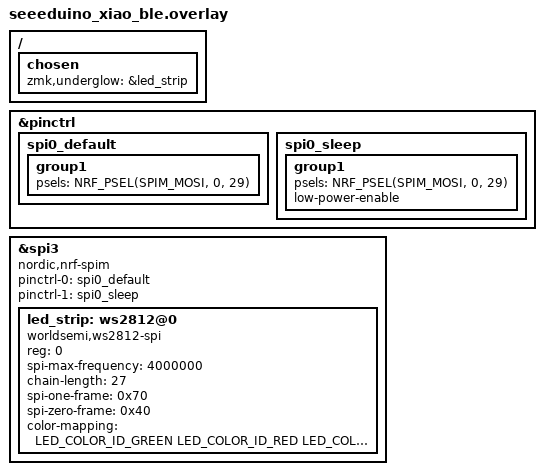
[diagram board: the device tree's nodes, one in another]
/*
ref: For future reference, this pinout shows both pin numberings https://files.seeedstudio.com/wiki/XIAO-BLE/pinout2.png
The &gpioX Y  and NRF_PSEL(..., X, Y) uses the PX.Y notation (underlying nRF pin numbers), &xiao_d x uses the unified pinout Dx
*/
#include <dt-bindings/led/led.h>

&pinctrl {
    spi0_default: spi0_default {
        group1 {
            psels = <NRF_PSEL(SPIM_MOSI, 0, 29)>;
        };
    };

    spi0_sleep: spi0_sleep {
        group1 {
            psels = <NRF_PSEL(SPIM_MOSI, 0, 29)>;
            low-power-enable;
        };
    };
};

&spi3 {
    compatible = "nordic,nrf-spim";
    status = "okay";

    pinctrl-0 = <&spi0_default>;
    pinctrl-1 = <&spi0_sleep>;
    pinctrl-names = "default", "sleep";

    led_strip: ws2812@0 {
        compatible = "worldsemi,ws2812-spi";
        // label = "WS2812";

        /* SPI */
        reg = <0>; /* ignored, but necessary for SPI bindings */
        spi-max-frequency = <4000000>;

        /* WS2812 */
        chain-length = <27>; /* arbitrary; change at will */
        spi-one-frame = <0x70>;
        spi-zero-frame = <0x40>;

        color-mapping = <LED_COLOR_ID_GREEN LED_COLOR_ID_RED LED_COLOR_ID_BLUE>;
    };
};

/ {
    chosen {
        zmk,underglow = &led_strip;
    };
};
// vim: filetype=dts fdm=marker:
